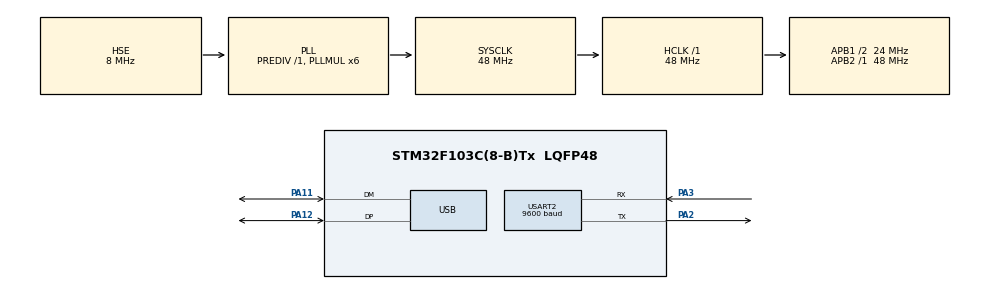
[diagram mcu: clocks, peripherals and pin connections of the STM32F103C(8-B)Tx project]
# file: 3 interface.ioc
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Mcu.Family=STM32F1
Mcu.Name=STM32F103C(8-B)Tx
Mcu.Package=LQFP48
NVIC.PriorityGroup=NVIC_PRIORITYGROUP_4
NVIC.USB_LP_CAN1_RX0_IRQn=true\:0\:0\:false\:false\:true\:false\:true
PA11.Mode=Device
PA11.Signal=USB_DM
PA12.Mode=Device
PA12.Signal=USB_DP
PA2.Mode=Asynchronous
PA2.Signal=USART2_TX
PA3.Mode=Asynchronous
PA3.Signal=USART2_RX
PD0-OSC_IN.Mode=HSE-External-Oscillator
PD0-OSC_IN.Signal=RCC_OSC_IN
PD1-OSC_OUT.Mode=HSE-External-Oscillator
PD1-OSC_OUT.Signal=RCC_OSC_OUT
ProjectManager.HeapSize=0x200
ProjectManager.StackSize=0x400
ProjectManager.TargetToolchain=MDK-ARM V5.27
RCC.AHBFreq_Value=48000000
RCC.APB1CLKDivider=RCC_HCLK_DIV2
RCC.APB1Freq_Value=24000000
RCC.APB1TimFreq_Value=48000000
RCC.APB2Freq_Value=48000000
RCC.APB2TimFreq_Value=48000000
RCC.HCLKFreq_Value=48000000
RCC.PLLMUL=RCC_PLL_MUL6
RCC.SYSCLKFreq_VALUE=48000000
RCC.SYSCLKSource=RCC_SYSCLKSOURCE_PLLCLK
RCC.USBFreq_Value=48000000
USART2.BaudRate=9600
USART2.VirtualMode=VM_ASYNC
USB_DEVICE.CLASS_NAME_FS=HID
USB_DEVICE.USBD_MAX_NUM_INTERFACES=3
USB_DEVICE.VirtualMode=Hid
USB_DEVICE.VirtualModeFS=Hid_FS
VP_SYS_VS_ND.Mode=No_Debug
VP_USB_DEVICE_VS_USB_DEVICE_HID_FS.Mode=HID_FS
board=custom

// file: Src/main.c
/* USER CODE BEGIN Header */
/**
  ******************************************************************************
  * @file           : main.c
  * @brief          : Main program body
  ******************************************************************************
  * @attention
  *
  * <h2><center>&copy; Copyright (c) 2020 STMicroelectronics.
  * All rights reserved.</center></h2>
  *
  * This software component is licensed by ST under Ultimate Liberty license
  * SLA0044, the "License"; You may not use this file except in compliance with
  * the License. You may obtain a copy of the License at:
  *                             www.st.com/SLA0044
  *
  ******************************************************************************
  */
/* USER CODE END Header */

#include "main.h"
#include "usb_device.h"
/* USER CODE BEGIN Includes */
 #include "usbd_hid.h"
/* USER CODE END Includes */
#include <string.h>
#define Page_Up	"PageUp"
#define Page_Down	"PageDown"

/* USER CODE BEGIN PM */
UART_HandleTypeDef huart2;
/* USER CODE END PM */

/*int fputc(int ch, FILE *f)
{
	HAL_UART_Transmit(&huart2, (uint8_t *)&ch, 1, 0xFFFF);
	return ch;
}*/
/* USER CODE BEGIN PV */
/*int fgetc( FILE *f)
{
	  int ret ;
    HAL_UART_Receive(&huart2, (uint8_t *)&ret, 1, 0xFFFF);
    return ret;
}*/

/* USER CODE END PV */

void SystemClock_Config(void);
static void MX_GPIO_Init(void);
static void MX_USART2_UART_Init(void);
//uint8_t Key_Scan(uint8_t GPIO_Pin);

int main(void)
{

  /* MCU Configuration--------------------------------------------------------*/

  /* Reset of all peripherals, Initializes the Flash interface and the Systick. */
  HAL_Init();

  /* Configure the system clock */
  SystemClock_Config();

  /* Initialize all configured peripherals */
	MX_USART2_UART_Init();
  MX_GPIO_Init();
  MX_USB_DEVICE_Init();

  /* Infinite loop */
  /* USER CODE BEGIN WHILE */
  while (1)
  {
		    char c[]="Page__Up";
		    char *d="PageDown";
		    char *e="-       ";
		    char a[8];
		    HAL_UART_Receive(&huart2,(uint8_t *)&a, 8 , 0xFFFF);
				//printf("a:%s \r\n",a);
			if(strcmp(a,c) == 0)
			{
			uint8_t report[8];
			report[0]= 0x00;
			report[1]= 0x00;
			report[2]= 0x4b;
			report[3]= 0x00;
			report[4]= 0x00;
			report[5]= 0x00;
			report[6]= 0x00;
			report[7]= 0x00;
			USBD_HID_SendReport_EP1(&hUsbDeviceFS,report, 8 , 0x81);
			HAL_Delay(40);
			report[0]= 0x00;
			report[1]= 0x00;
			report[2]= 0x00;
			report[3]= 0x00;
			report[4]= 0x00;
			report[5]= 0x00;
			report[6]= 0x00;
			report[7]= 0x00;
			USBD_HID_SendReport_EP1(&hUsbDeviceFS,report, 8 , 0x81);
		  HAL_Delay(40);
			for(int i = 0;i<8;i++)
			a[i]=0;

			//printf("a: %s \r\n",a);
			}

			else if(strcmp(a,d) == 0)
			{
			uint8_t report[8];
			report[0]= 0x00;
			report[1]= 0x00;
			report[2]= 0x4e;
			report[3]= 0x00;
			report[4]= 0x00;
			report[5]= 0x00;
			report[6]= 0x00;
			report[7]= 0x00;
			USBD_HID_SendReport_EP1(&hUsbDeviceFS,report, 8 , 0x81);
			HAL_Delay(40);
			report[0]= 0x00;
			report[1]= 0x00;
			report[2]= 0x00;
			report[3]= 0x00;
			report[4]= 0x00;
			report[5]= 0x00;
			report[6]= 0x00;
			report[7]= 0x00;
			USBD_HID_SendReport_EP1(&hUsbDeviceFS,report, 8 , 0x81);
      HAL_Delay(40);
		  for(int i = 0;i<8;i++)
			a[i]=0;

			//printf("s: %s \r\n",a);
			}
			else if(strcmp(a,e) == 0)
			{
			uint8_t report[8];
			report[0]= 0x00;
			report[1]= 0x00;
			report[2]= 0x56;
			report[3]= 0x00;
			report[4]= 0x00;
			report[5]= 0x00;
			report[6]= 0x00;
			report[7]= 0x00;
			USBD_HID_SendReport_EP1(&hUsbDeviceFS,report, 8 , 0x81);
			HAL_Delay(40);
			report[0]= 0x00;
			report[1]= 0x00;
			report[2]= 0x00;
			report[3]= 0x00;
			report[4]= 0x00;
			report[5]= 0x00;
			report[6]= 0x00;
			report[7]= 0x00;
			USBD_HID_SendReport_EP1(&hUsbDeviceFS,report, 8 , 0x81);
      HAL_Delay(40);
		  for(int i = 0;i<8;i++)
			a[i]=0;
			}
    else
		  {
			for(int i = 0;i<8;i++)
			a[i]=0;
		  }
  }
}

static void MX_USART2_UART_Init(void)
{

  huart2.Instance = USART2;
  huart2.Init.BaudRate = 9600;
  huart2.Init.WordLength = UART_WORDLENGTH_8B;
  huart2.Init.StopBits = UART_STOPBITS_1;
  huart2.Init.Parity = UART_PARITY_NONE;
  huart2.Init.Mode = UART_MODE_TX_RX;
  huart2.Init.HwFlowCtl = UART_HWCONTROL_NONE;
  huart2.Init.OverSampling = UART_OVERSAMPLING_16;
  if (HAL_UART_Init(&huart2) != HAL_OK)
  {
    Error_Handler();
  }
}
void SystemClock_Config(void)
{
  RCC_OscInitTypeDef RCC_OscInitStruct = {0};
  RCC_ClkInitTypeDef RCC_ClkInitStruct = {0};
  RCC_PeriphCLKInitTypeDef PeriphClkInit = {0};

  /** Initializes the CPU, AHB and APB busses clocks
  */
  RCC_OscInitStruct.OscillatorType = RCC_OSCILLATORTYPE_HSE;
  RCC_OscInitStruct.HSEState = RCC_HSE_ON;
  RCC_OscInitStruct.HSEPredivValue = RCC_HSE_PREDIV_DIV1;
  RCC_OscInitStruct.HSIState = RCC_HSI_ON;
  RCC_OscInitStruct.PLL.PLLState = RCC_PLL_ON;
  RCC_OscInitStruct.PLL.PLLSource = RCC_PLLSOURCE_HSE;
  RCC_OscInitStruct.PLL.PLLMUL = RCC_PLL_MUL6;
  if (HAL_RCC_OscConfig(&RCC_OscInitStruct) != HAL_OK)
  {
    Error_Handler();
  }
  /** Initializes the CPU, AHB and APB busses clocks
  */
  RCC_ClkInitStruct.ClockType = RCC_CLOCKTYPE_HCLK|RCC_CLOCKTYPE_SYSCLK
                              |RCC_CLOCKTYPE_PCLK1|RCC_CLOCKTYPE_PCLK2;
  RCC_ClkInitStruct.SYSCLKSource = RCC_SYSCLKSOURCE_PLLCLK;
  RCC_ClkInitStruct.AHBCLKDivider = RCC_SYSCLK_DIV1;
  RCC_ClkInitStruct.APB1CLKDivider = RCC_HCLK_DIV2;
  RCC_ClkInitStruct.APB2CLKDivider = RCC_HCLK_DIV1;

  if (HAL_RCC_ClockConfig(&RCC_ClkInitStruct, FLASH_LATENCY_1) != HAL_OK)
  {
    Error_Handler();
  }
  PeriphClkInit.PeriphClockSelection = RCC_PERIPHCLK_USB;
  PeriphClkInit.UsbClockSelection = RCC_USBCLKSOURCE_PLL;
  if (HAL_RCCEx_PeriphCLKConfig(&PeriphClkInit) != HAL_OK)
  {
    Error_Handler();
  }
}

static void MX_GPIO_Init(void)
{
  GPIO_InitTypeDef GPIOx;
  /* GPIO Ports Clock Enable */
  __HAL_RCC_GPIOD_CLK_ENABLE();
  __HAL_RCC_GPIOA_CLK_ENABLE();

	GPIOx.Pin   = GPIO_PIN_0;
	GPIOx.Mode  = GPIO_MODE_INPUT;
  GPIOx.Pull  = GPIO_NOPULL;
	GPIOx.Speed = GPIO_SPEED_FREQ_HIGH;
	HAL_GPIO_Init(GPIOA,&GPIOx);

}

/* USER CODE BEGIN 4 */
/*uint8_t Key_Scan(uint8_t GPIO_Pin)

{

	if(GPIO_Pin == KEY_ON )
	{

		printf("key: %d \r\n",GPIO_Pin);
		uint8_t report[8];
    report[0]= 0x00;
    report[1]= 0x00;
    report[2]= 0x04;
		report[3]= 0x00;
		report[4]= 0x00;
		report[5]= 0x00;
		report[6]= 0x00;
		report[7]= 0x00;
    USBD_HID_SendReport_EP1(&hUsbDeviceFS,report, 8 , 0x81);
    HAL_Delay(30);
    key = 0;
		while(GPIO_Pin == KEY_ON)
		{

		}

			return 	KEY_ON;

	}
	else
	{
		key = 0;
		return KEY_OFF;
	}
}*/
/* USER CODE END 4 */

void Error_Handler(void)
{
}

/************************ (C) COPYRIGHT STMicroelectronics *****END OF FILE****/
